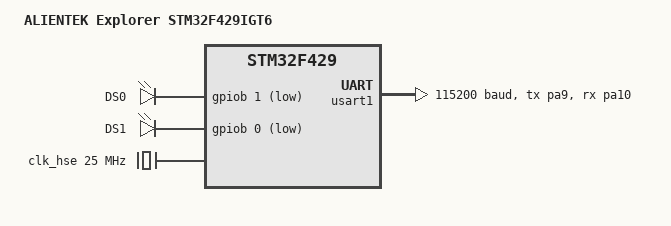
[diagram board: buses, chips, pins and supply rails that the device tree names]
/*
 * SPDX-License-Identifier: Apache-2.0
 *
 * ALIENTEK Explorer STM32F429IGT6 board.
 * Only the nodes used by the bare-metal port are enabled; everything else
 * stays disabled as defined by the upstream SoC dtsi.
 */

/dts-v1/;

#include <st/f4/stm32f429Xi.dtsi>
#include <zephyr/dt-bindings/gpio/gpio.h>
#include <zephyr/dt-bindings/pinctrl/stm32-pinctrl.h>
#include <zephyr/dt-bindings/dma/stm32_dma.h>

/ {
	model = "ALIENTEK Explorer STM32F429IGT6";
	compatible = "alientek,explorer-f429", "st,stm32f429";

	chosen {
		zephyr,console = &usart1;
		zephyr,shell-uart = &usart1;
		zephyr,flash = &flash0;
		zephyr,sram = &sram0;
	};

	leds: leds {
		compatible = "gpio-leds";

		led0: led_0 {
			gpios = <&gpiob 1 GPIO_ACTIVE_LOW>;
			label = "DS0";
		};

		led1: led_1 {
			gpios = <&gpiob 0 GPIO_ACTIVE_LOW>;
			label = "DS1";
		};
	};

	aliases {
		led0 = &led0;
	};
};

/* IGT6 has 1 MB of flash; the upstream Xi variant describes 2 MB. */
&flash0 {
	reg = <0x08000000 DT_SIZE_K(1024)>;
};

/*
 * Explorer board fits a 25 MHz HSE crystal; the SoC default is 16 MHz and the
 * node is disabled in the SoC dtsi, so it must be enabled explicitly - without
 * this the PLL is told to use HSE but HSE is never started.
 */
&clk_hse {
	status = "okay";
	clock-frequency = <DT_FREQ_M(25)>;
};

/* 25 MHz / 25 * 360 / 2 = 180 MHz */
&pll {
	clocks = <&clk_hse>;
	div-m = <25>;
	mul-n = <360>;
	div-p = <2>;
	div-q = <7>;
	status = "okay";
};

&rcc {
	clocks = <&pll>;
	clock-frequency = <DT_FREQ_M(180)>;
	ahb-prescaler = <1>;
	apb1-prescaler = <4>;
	apb2-prescaler = <2>;
};

&gpiob {
	status = "okay";
};

/* USART1 TX is DMA2 stream 7 / channel 4, RX is stream 2 / channel 4. */
&dma2 {
	status = "okay";
};

&pinctrl {
	usart1_tx_pa9: usart1_tx_pa9 {
		pinmux = <STM32_PINMUX('A', 9, AF7)>;
	};

	usart1_rx_pa10: usart1_rx_pa10 {
		pinmux = <STM32_PINMUX('A', 10, AF7)>;
	};
};

&usart1 {
	dmas = <&dma2 7 4 (STM32_DMA_PERIPH_TX | STM32_DMA_PRIORITY_HIGH) 0>,
	       <&dma2 2 4 (STM32_DMA_PERIPH_RX | STM32_DMA_PRIORITY_HIGH) 0>;
	dma-names = "tx", "rx";
	pinctrl-0 = <&usart1_tx_pa9 &usart1_rx_pa10>;
	pinctrl-names = "default";
	current-speed = <115200>;
	status = "okay";
};
